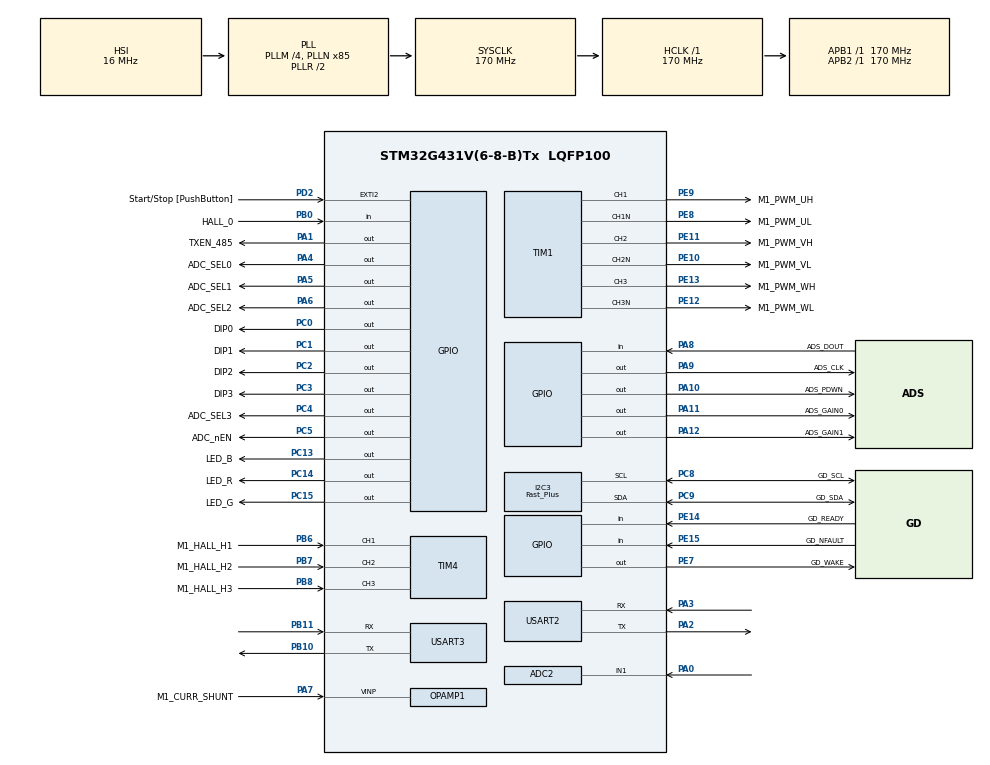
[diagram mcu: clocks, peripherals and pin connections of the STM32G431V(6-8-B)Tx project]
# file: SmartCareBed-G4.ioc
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ADC1.ClockPrescaler=ADC_CLOCK_ASYNC_DIV1
ADC1.ContinuousConvMode=DISABLE
ADC1.DMAContinuousRequests=DISABLE
ADC1.DataAlign=ADC_DATAALIGN_LEFT
ADC1.DiscontinuousConvMode=DISABLE
ADC1.EOCSelection=ADC_EOC_SINGLE_CONV
ADC1.EnableAnalogWatchDog1=false
ADC1.EnableAnalogWatchDog2=false
ADC1.EnableAnalogWatchDog3=false
ADC1.EnableInjectedConversion=ENABLE
ADC1.EnableRegularConversion=DISABLE
ADC1.ExternalTrigInjecConv=ADC_EXTERNALTRIGINJEC_T1_TRGO
ADC1.ExternalTrigInjecConvEdge=ADC_EXTERNALTRIGINJECCONV_EDGE_RISINGFALLING
ADC1.InjNumberOfConversion=2
ADC1.InjectedChannel-1\#ChannelInjectedConversion=ADC_CHANNEL_VOPAMP1
ADC1.InjectedChannel-2\#ChannelInjectedConversion=ADC_CHANNEL_VOPAMP1
ADC1.InjectedConvMode=None
ADC1.InjectedOffset-1\#ChannelInjectedConversion=0
ADC1.InjectedOffset-2\#ChannelInjectedConversion=0
ADC1.InjectedOffsetNumber-1\#ChannelInjectedConversion=ADC_OFFSET_NONE
ADC1.InjectedOffsetNumber-2\#ChannelInjectedConversion=ADC_OFFSET_NONE
ADC1.InjectedRank-1\#ChannelInjectedConversion=1
ADC1.InjectedRank-2\#ChannelInjectedConversion=2
ADC1.InjectedSamplingTime-1\#ChannelInjectedConversion=ADC_SAMPLETIME_6CYCLES_5
ADC1.InjectedSamplingTime-2\#ChannelInjectedConversion=ADC_SAMPLETIME_6CYCLES_5
ADC1.LowPowerAutoWait=DISABLE
ADC1.Overrun=ADC_OVR_DATA_PRESERVED
ADC1.Resolution=ADC_RESOLUTION_12B
ADC1.ScanConvMode=ADC_SCAN_ENABLE
ADC1.master=1
ADC2.Channel-1\#ChannelRegularConversion=ADC_CHANNEL_1
ADC2.ClockPrescaler=ADC_CLOCK_ASYNC_DIV1
ADC2.NbrOfConversionFlag=1
ADC2.OffsetNumber-1\#ChannelRegularConversion=ADC_OFFSET_NONE
ADC2.Rank-1\#ChannelRegularConversion=1
ADC2.SamplingTime-1\#ChannelRegularConversion=ADC_SAMPLETIME_2CYCLES_5
Dma.Request0=TIM1_CH4
Dma.TIM1_CH4.0.Direction=DMA_MEMORY_TO_PERIPH
Dma.TIM1_CH4.0.EventEnable=DISABLE
Dma.TIM1_CH4.0.Instance=DMA1_Channel1
Dma.TIM1_CH4.0.MemDataAlignment=DMA_MDATAALIGN_HALFWORD
Dma.TIM1_CH4.0.MemInc=DMA_MINC_ENABLE
Dma.TIM1_CH4.0.Mode=DMA_CIRCULAR
Dma.TIM1_CH4.0.PeriphDataAlignment=DMA_PDATAALIGN_HALFWORD
Dma.TIM1_CH4.0.PeriphInc=DMA_PINC_DISABLE
Dma.TIM1_CH4.0.Polarity=HAL_DMAMUX_REQ_GEN_RISING
Dma.TIM1_CH4.0.Priority=DMA_PRIORITY_HIGH
Dma.TIM1_CH4.0.RequestNumber=1
Dma.TIM1_CH4.0.SignalID=NONE
Dma.TIM1_CH4.0.SyncEnable=DISABLE
Dma.TIM1_CH4.0.SyncPolarity=HAL_DMAMUX_SYNC_NO_EVENT
Dma.TIM1_CH4.0.SyncRequestNumber=1
Dma.TIM1_CH4.0.SyncSignalID=NONE
ExtraMW=MotorControl
ExtraMW.MotorControl.Config=MotorControl
ExtraMW.MotorControl.Mode=MotorControl
ExtraMW.MotorControl.Root=MCSDK_v6.3.2-Full/MotorControl
ExtraMW.MotorControl.Template=templates
I2C3.I2C_Speed_Mode=I2C_Fast_Plus
I2C3.Timing=0x4052060F
Mcu.Family=STM32G4
Mcu.Name=STM32G431V(6-8-B)Tx
Mcu.Package=LQFP100
MotorControl.ADC_AHBPERIPH=RCC_AHBPeriph_ADC1
MotorControl.ADC_CLOCK_WB_DIV=1
MotorControl.ADC_PERIPH=ADC1
MotorControl.ADC_REFERENCE_VOLTAGE=3.3
MotorControl.BOARD=EVSPIN32G4
MotorControl.BUS_VOLTAGE_READING=false
MotorControl.CCMRAM_ENABLED=false
MotorControl.CLOCK_FREQUENCY=CPU_CLK_170_MHZ
MotorControl.CLOCK_SOURCE=INTERNAL
MotorControl.CPU_CLK_170_MHZ=true
MotorControl.CTLBOARD_NAME=EVSPIN32G4
MotorControl.CUBE_MX_VER=6.14.0
MotorControl.CURRENT_READING_TOPOLOGY=SINGLE_SHUNT
MotorControl.CURR_SAMPLING_TIME=6
MotorControl.DBG_MCU_LOAD_MEASURE=false
MotorControl.DEBUG_DAC_FUNCTIONALITY_EN=false
MotorControl.DRIVES_NUMBER_SELECTION=SINGLEDRIVE
MotorControl.DRIVE_NUMBER=1
MotorControl.DRIVE_TYPE=FOC
MotorControl.ENCODER_AVAILABLE=false
MotorControl.ENCODER_PPR=400
MotorControl.EXT_CLOCK_FREQUENCY=INT_RC_OSC
MotorControl.FEEDBACK_NET_FILTERING=false
MotorControl.FLASH_SIZE=128
MotorControl.H1_GPIO_PIN=LL_GPIO_PIN_6
MotorControl.H1_GPIO_PORT=GPIOB
MotorControl.H2_GPIO_PIN=LL_GPIO_PIN_7
MotorControl.H2_GPIO_PORT=GPIOB
MotorControl.H3_GPIO_PIN=LL_GPIO_PIN_8
MotorControl.H3_GPIO_PORT=GPIOB
MotorControl.HALL_ICx_FILTER=119
MotorControl.HALL_SENSORS=true
MotorControl.HALL_SENSORS_AVAILABLE=true
MotorControl.HALL_TIMER_SELECTION=HALL_TIM4
MotorControl.HIGH_SIDE_IDLE_STATE=false
MotorControl.HWV_CS=SingleShunt_RawCurrents_SingleEnded_InternalGain
MotorControl.HWV_PWM=PoweringHighAndLowSides
MotorControl.HW_COMPLEMENTED_LOW_SIDE=false
MotorControl.HW_DEAD_TIME_NS=1000
MotorControl.INT_RC_OSC=true
MotorControl.IPs=I2C3,CORDIC,SYS,NVIC,RCC,MotorControl,OPAMP1,ADC1,TIM1,TIM4,DMA
MotorControl.LOW_MEMORY_FOOTPRINT_REG=false
MotorControl.LOW_SIDE_IDLE_STATE=false
MotorControl.LOW_SIDE_SIGNALS_ENABLING=LS_PWM_TIMER
MotorControl.M1_AMPLIFICATION_GAIN=7.04
MotorControl.M1_ANGC={0,0,0,0,0,0,0,0}
MotorControl.M1_AUXILIARY_SPEED_SENSOR=NONE
MotorControl.M1_BOARD_MAX_CURRENT=1.5
MotorControl.M1_BUS_VOLTAGE_READING=false
MotorControl.M1_COMMUTATION_STEP_TIME_BUF_SIZE=12
MotorControl.M1_CONSTANT1_D=701888
MotorControl.M1_CONSTANT1_Q=701888
MotorControl.M1_CONSTANT2_QD=24322
MotorControl.M1_CS_ADC_NUM=1
MotorControl.M1_CS_ADC_PHASE_SHARED=NONE
MotorControl.M1_CS_ADC_U=ADC1
MotorControl.M1_CS_CHANNEL_U=VPOPAMP1
MotorControl.M1_CS_OPAMP_DIRECT_LINK_TO_ADC=ADC1
MotorControl.M1_CS_OPAMP_DYNAMIC_OUTPUT_SWITCH=false
MotorControl.M1_CS_OPAMP_NUM=1
MotorControl.M1_CS_OPAMP_PHASE_SHARED=NONE
MotorControl.M1_CS_OPAMP_U=OPAMP1
MotorControl.M1_CS_OPAMP_VPSEL_U=PA7
MotorControl.M1_CURRENT_AMPLIFICATION_TOPO=INT_SINGLE_ENDED
MotorControl.M1_CURRENT_SENSING_TOPO=SINGLE_SHUNT_PHASE_SHIFT
MotorControl.M1_CURR_SAMPLING_TIME=6
MotorControl.M1_DBG_OPEN_LOOP_ENABLE=false
MotorControl.M1_DC_CURRENT_RS_MEAS=1.5
MotorControl.M1_DEFAULT_CONTROL_MODE=STC_SPEED_MODE
MotorControl.M1_DEFAULT_FLUX_COMPONENT=0
MotorControl.M1_DEFAULT_TARGET_SPEED_RPM=4000
MotorControl.M1_DEFAULT_TORQUE_COMPONENT=0
MotorControl.M1_DISCONTINUOUS_PWM=false
MotorControl.M1_DP_TOPOLOGY=NONE
MotorControl.M1_DRIVE_TYPE=FOC
MotorControl.M1_ENCODER_PPR=400
MotorControl.M1_FEED_FORWARD_CURRENT_REG_ENABLING=false
MotorControl.M1_FLUX_WEAKENING_ENABLING=false
MotorControl.M1_FW_KIDIV=32768
MotorControl.M1_FW_KI_GAIN=5000
MotorControl.M1_FW_KPDIV=32768
MotorControl.M1_FW_KP_GAIN=3000
MotorControl.M1_FW_VOLTAGE_REF=985
MotorControl.M1_HALL_AVERAGING_FIFO_DEPTH=16
MotorControl.M1_HALL_ICx_FILTER=119
MotorControl.M1_HALL_MTPA=false
MotorControl.M1_HALL_PHASE_SHIFT=300
MotorControl.M1_HALL_SENSORS_PLACEMENT=DEGREES_120
MotorControl.M1_HALL_TIMER_IRQ=TIM4
MotorControl.M1_HALL_TIMER_SELECTION=HALL_TIM4
MotorControl.M1_HIGH_SIDE_IDLE_STATE=false
MotorControl.M1_HW_DEAD_TIME_NS=1000
MotorControl.M1_ICL_ENABLED=false
MotorControl.M1_ID_DEMAG=-1.5
MotorControl.M1_INT_AMP_OPAMP1_PIN=[{'mode'\:'Standalone','name'\:'PA7','signal'\:'OPAMP1_VINP','label'\:'SHUNT_P_P'}]
MotorControl.M1_INT_AMP_OPAMPS=['OPAMP1']
MotorControl.M1_IQMAX=1.5
MotorControl.M1_LDLQ_RATIO=1.000
MotorControl.M1_LOW_SIDE_IDLE_STATE=false
MotorControl.M1_LOW_SIDE_SIGNALS_ENABLING=LS_PWM_TIMER
MotorControl.M1_LS=0.0006
MotorControl.M1_MAX_APPLICATION_SPEED=4000
MotorControl.M1_MAX_MODULATION_INDEX=100
MotorControl.M1_MIN_APPLICATION_SPEED=0
MotorControl.M1_MOTOR_MAX_SPEED_RPM=4000
MotorControl.M1_MOTOR_NAME=Shinano LA052-080E3NL1
MotorControl.M1_MOTOR_RATED_FLUX=0.048989795
MotorControl.M1_MOTOR_VOLTAGE_CONSTANT=4.0
MotorControl.M1_MTPA_ENABLING=false
MotorControl.M1_NOMINAL_BUS_VOLTAGE_V=24
MotorControl.M1_NOMINAL_CURRENT=1.5
MotorControl.M1_OCP_TOPOLOGY=NONE
MotorControl.M1_OFST={0,0,0,0,0,0,0,0}
MotorControl.M1_OVERMODULATION=false
MotorControl.M1_PID_FLUX_KD_DEFAULT=100
MotorControl.M1_PID_FLUX_KI_DEFAULT=3360
MotorControl.M1_PID_FLUX_KP_DEFAULT=3600
MotorControl.M1_PID_SPEED_KD_DEFAULT=0
MotorControl.M1_PID_SPEED_KI_DEFAULT=362
MotorControl.M1_PID_SPEED_KP_DEFAULT=2019
MotorControl.M1_PID_TORQUE_KD_DEFAULT=100
MotorControl.M1_PID_TORQUE_KI_DEFAULT=3360
MotorControl.M1_PID_TORQUE_KP_DEFAULT=3600
MotorControl.M1_POLE_PAIR_NUM=4
MotorControl.M1_POSITION_CTRL_ENABLING=false
MotorControl.M1_POTENTIOMETER_ENABLE=false
MotorControl.M1_POWERBOARD_NAME=EVSPIN32G4
MotorControl.M1_PWM_CHARGE_BOOT_CAP_DUTY_CYCLES=0.000
MotorControl.M1_PWM_CHARGE_BOOT_CAP_MS=10
MotorControl.M1_PWM_DRIVER_PN=STSPIN32G4
MotorControl.M1_PWM_FREQUENCY=20000
MotorControl.M1_PWM_TIMER_BRK_IRQ=TIM1_BRK_TIM15
MotorControl.M1_PWM_TIMER_SELECTION=PWM_TIM1
MotorControl.M1_PWM_TIMER_UP_IRQ=TIM1_UP_TIM16
MotorControl.M1_REGULATION_EXECUTION_RATE=1
MotorControl.M1_RS=0.35
MotorControl.M1_RSHUNT=0.005
MotorControl.M1_SEGDIV=0
MotorControl.M1_SHARED_SIGNAL_ENABLE=false
MotorControl.M1_SPD_DIFFERENTIAL_TERM_ENABLING=false
MotorControl.M1_SPEED_LOOP_FREQUENCY_HZ=1000
MotorControl.M1_SPEED_SENSOR=HALL_SENSOR
MotorControl.M1_SP_KDDIV=16
MotorControl.M1_SP_KIDIV=16384
MotorControl.M1_SP_KPDIV=256
MotorControl.M1_SS_MEAS_ERRORS_BEFORE_FAULTS=3
MotorControl.M1_SW_DEADTIME_NS=750
MotorControl.M1_TEMPERATURE_READING=false
MotorControl.M1_TF_KDDIV=8192
MotorControl.M1_TF_KIDIV=8192
MotorControl.M1_TF_KPDIV=256
MotorControl.M1_TNOISE_NS=1200
MotorControl.M1_TRISE_NS=61
MotorControl.M1_USE_INTERNAL_OPAMP=true
MotorControl.MAX_READABLE_CURRENT=46.875
MotorControl.MCP_EN=false
MotorControl.MCU=STSPIN32G4
MotorControl.MCU_FAMILY=STM32G4
MotorControl.MCU_LINE=STM32G4x1
MotorControl.MCU_NAME=STM32G431V(6-8-B)Tx
MotorControl.MCU_PACKAGE=LQFP100
MotorControl.MCU_TYPE=STSPIN32G4
MotorControl.MCU_USERNAME=STM32G431VBTx
MotorControl.MC_WORKBENCH_VERSION=6.3.2
MotorControl.MOTOR_PROFILER=false
MotorControl.MOTOR_TYPE=PMSM
MotorControl.OPAMP_INVERTINGINPUT_MODE=INT_MODE
MotorControl.OPAMP_NONINVERTINGINPUT=OPAMP1_NonInvertingInput_PA7
MotorControl.OPAMP_NONINVERTINGINPUT_GPIO_PIN=LL_GPIO_PIN_7
MotorControl.OPAMP_NONINVERTINGINPUT_GPIO_PORT=GPIOA
MotorControl.OPAMP_PGAGAIN=OPAMP_OPAMP_PGAGain_8
MotorControl.OPAMP_SELECTION=OPAMP1
MotorControl.OPAMP_TYPE_GAIN=INTERNAL
MotorControl.PHASE_CURRENTS_ADC=ADC1
MotorControl.PHASE_CURRENTS_CHANNEL=ADC_Channel_VOPAMP1
MotorControl.PHASE_CURRENTS_GPIO_PIN=VIRTUAL_PIN
MotorControl.PHASE_CURRENTS_GPIO_PORT=VIRTUAL_PORT
MotorControl.PHASE_UH_GPIO_PIN=LL_GPIO_PIN_9
MotorControl.PHASE_UH_GPIO_PORT=GPIOE
MotorControl.PHASE_UH_POLARITY=H_ACTIVE_HIGH
MotorControl.PHASE_UL_GPIO_PIN=LL_GPIO_PIN_8
MotorControl.PHASE_UL_GPIO_PORT=GPIOE
MotorControl.PHASE_UL_POLARITY=L_ACTIVE_HIGH
MotorControl.PHASE_U_PWM_CHANNEL=TIM_Channel_1
MotorControl.PHASE_VH_GPIO_PIN=LL_GPIO_PIN_11
MotorControl.PHASE_VH_GPIO_PORT=GPIOE
MotorControl.PHASE_VH_POLARITY=H_ACTIVE_HIGH
MotorControl.PHASE_VL_GPIO_PIN=LL_GPIO_PIN_10
MotorControl.PHASE_VL_GPIO_PORT=GPIOE
MotorControl.PHASE_VL_POLARITY=L_ACTIVE_HIGH
MotorControl.PHASE_V_PWM_CHANNEL=TIM_Channel_2
MotorControl.PHASE_WH_GPIO_PIN=LL_GPIO_PIN_13
MotorControl.PHASE_WH_GPIO_PORT=GPIOE
MotorControl.PHASE_WH_POLARITY=H_ACTIVE_HIGH
MotorControl.PHASE_WL_GPIO_PIN=LL_GPIO_PIN_12
MotorControl.PHASE_WL_GPIO_PORT=GPIOE
MotorControl.PHASE_WL_POLARITY=L_ACTIVE_HIGH
MotorControl.PHASE_W_PWM_CHANNEL=TIM_Channel_3
MotorControl.POTENTIOMETER_READING=false
MotorControl.PWM_FREQUENCY=20000
MotorControl.PWM_TIMER_SELECTION=PWM_TIM1
MotorControl.REGULATION_EXECUTION_RATE=1
MotorControl.RTOS=NONE
MotorControl.SINGLEDRIVE=true
MotorControl.SINGLE_SHUNT=true
MotorControl.SPD_DIFFERENTIAL_TERM_ENABLING=false
MotorControl.SPEED_SENSOR_SELECTION=HALL_SENSORS
MotorControl.START_STOP_BTN=true
MotorControl.START_STOP_GPIO_PIN=LL_GPIO_PIN_10
MotorControl.START_STOP_GPIO_PORT=GPIOB
MotorControl.START_STOP_POLARITY=DIN_ACTIVE_HIGH
MotorControl.START_STOP_POLARITY_EDGE=GPIO_NOPULL
MotorControl.STSPIN32G4=true
MotorControl.SW_DEADTIME_NS=750
MotorControl.TEMPERATURE_READING=false
MotorControl.TFDIFFERENTIAL_TERM_ENABLING=false
MotorControl.TRISE_NS=61
MotorControl.USE_3OPAMPS=false
MotorControl.USE_INTERNAL_OPAMP=true
MotorControl.WB_UI_CUTOFF_FREQUENCY=6000
MotorControl.WB_UI_ENCODER_HAS_INDEX_PIN=false
MotorControl.WB_UI_FLUX_TARGET=0
MotorControl.WB_UI_FRICTION=14
MotorControl.WB_UI_GAIN=7.04
MotorControl.WB_UI_GAINLIST=[{'factor'\:2,'gain'\:1.76,'pol'\:0.396,'maxVRef'\:3.3},{'factor'\:4,'gain'\:3.52,'pol'\:0.792,'maxVRef'\:3.3},{'factor'\:8,'gain'\:7.04,'pol'\:1.584,'maxVRef'\:3.3},{'factor'\:16,'gain'\:14.08,'pol'\:3.168,'maxVRef'\:3.3},{'factor'\:32,'gain'\:28.16,'pol'\:6.336,'maxVRef'\:3.3},{'factor'\:64,'gain'\:56.32,'pol'\:12.672,'maxVRef'\:3.3}]
MotorControl.WB_UI_GON=0.88
MotorControl.WB_UI_GOP=8
MotorControl.WB_UI_INERTIA=5
MotorControl.WB_UI_MAGNETIC_STRUCTURE=SM-PMSM
MotorControl.WB_UI_MAX_CURRENT=1.5
MotorControl.WB_UI_MAX_NOMINAL_DC_VOLTAGE=24
MotorControl.WB_UI_MAX_PWMFREQUENCY=100000
MotorControl.WB_UI_MOTOR_DESCRIPTION=Inner rotor type - 2 poles pairs - brushless DC motor with encoder
MotorControl.WB_UI_PW_BOARD_MAX_RATED_CURRENT=20
MotorControl.WB_UI_PW_BOARD_MAX_VOLTAGE=75
MotorControl.WB_UI_PW_BOARD_MIN_VOLTAGE=10
MotorControl.WB_UI_VPOL=1.5840633625
MotorControl.WB_UI_VPOL_K=0.1980079203
MotorControl.WB_to_Mx_template_version=24-04-17
MotorControl.WB_to_Mx_version=6.2.3
NVIC.ADC1_2_IRQn=true\:2\:0\:true\:true\:false\:2\:true\:true\:true
NVIC.DMA1_Channel1_IRQn=true\:0\:0\:true\:true\:false\:1\:true\:true\:true
NVIC.EXTI2_IRQn=true\:3\:0\:true\:false\:true\:true\:true\:true
NVIC.PriorityGroup=NVIC_PRIORITYGROUP_3
NVIC.TIM1_BRK_TIM15_IRQn=true\:4\:1\:true\:true\:false\:3\:true\:true\:true
NVIC.TIM1_UP_TIM16_IRQn=true\:0\:0\:false\:true\:false\:4\:true\:true\:true
NVIC.TIM4_IRQn=true\:3\:0\:false\:true\:false\:5\:true\:true\:true
OPAMP1.PgaGain=OPAMP_PGA_GAIN_8_OR_MINUS_7
OPAMP1.SelfCalibration=Disable
PA0.Mode=IN1-Single-Ended
PA0.Signal=ADC2_IN1
PA1.GPIO_Label=TXEN_485
PA1.Signal=GPIO_Output
PA10.GPIO_Label=ADS_PDWN
PA10.Signal=GPIO_Output
PA11.GPIO_Label=ADS_GAIN0
PA11.Signal=GPIO_Output
PA12.GPIO_Label=ADS_GAIN1
PA12.Signal=GPIO_Output
PA13.GPIO_Label=TMS
PA13.Mode=Serial_Wire
PA13.Signal=SYS_JTMS-SWDIO
PA14.GPIO_Label=TCK
PA14.Mode=Serial_Wire
PA14.Signal=SYS_JTCK-SWCLK
PA2.Mode=Asynchronous
PA2.Signal=USART2_TX
PA3.Mode=Asynchronous
PA3.Signal=USART2_RX
PA4.GPIO_Label=ADC_SEL0
PA4.Signal=GPIO_Output
PA5.GPIO_Label=ADC_SEL1
PA5.Signal=GPIO_Output
PA6.GPIO_Label=ADC_SEL2
PA6.Signal=GPIO_Output
PA7.GPIO_Label=M1_CURR_SHUNT
PA7.Mode=PGA_Internally_Connected
PA7.Signal=OPAMP1_VINP
PA8.GPIO_Label=ADS_DOUT
PA8.Signal=GPIO_Input
PA9.GPIO_Label=ADS_CLK
PA9.Signal=GPIO_Output
PB0.GPIO_Label=HALL_0
PB0.Signal=GPIO_Input
PB10.Mode=Asynchronous
PB10.Signal=USART3_TX
PB11.Mode=Asynchronous
PB11.Signal=USART3_RX
PB6.GPIO_Label=M1_HALL_H1
PB6.GPIO_Speed=GPIO_SPEED_FREQ_HIGH
PB6.Signal=S_TIM4_CH1
PB7.GPIO_Label=M1_HALL_H2
PB7.GPIO_Speed=GPIO_SPEED_FREQ_HIGH
PB7.Signal=S_TIM4_CH2
PB8-BOOT0.GPIO_Label=M1_HALL_H3
PB8-BOOT0.GPIO_Speed=GPIO_SPEED_FREQ_HIGH
PB8-BOOT0.Signal=S_TIM4_CH3
PC0.GPIO_Label=DIP0
PC0.Signal=GPIO_Output
PC1.GPIO_Label=DIP1
PC1.Signal=GPIO_Output
PC13.GPIO_Label=LED_B
PC13.Signal=GPIO_Output
PC14-OSC32_IN.GPIO_Label=LED_R
PC14-OSC32_IN.Signal=GPIO_Output
PC15-OSC32_OUT.GPIO_Label=LED_G
PC15-OSC32_OUT.Signal=GPIO_Output
PC2.GPIO_Label=DIP2
PC2.Signal=GPIO_Output
PC3.GPIO_Label=DIP3
PC3.Signal=GPIO_Output
PC4.GPIO_Label=ADC_SEL3
PC4.Signal=GPIO_Output
PC5.GPIO_Label=ADC_nEN
PC5.Signal=GPIO_Output
PC8.GPIO_Label=GD_SCL
PC8.Mode=I2C
PC8.Signal=I2C3_SCL
PC9.GPIO_Label=GD_SDA
PC9.Mode=I2C
PC9.Signal=I2C3_SDA
PD2.GPIO_Label=Start/Stop [PushButton]
PD2.Signal=GPXTI2
PE10.GPIO_Label=M1_PWM_VL
PE10.GPIO_PuPd=GPIO_PULLDOWN
PE10.GPIO_Speed=GPIO_SPEED_FREQ_HIGH
PE10.Mode=PWM Generation2 CH2 CH2N
PE10.Signal=TIM1_CH2N
PE11.GPIO_Label=M1_PWM_VH
PE11.GPIO_PuPd=GPIO_PULLDOWN
PE11.GPIO_Speed=GPIO_SPEED_FREQ_HIGH
PE11.Signal=S_TIM1_CH2
PE12.GPIO_Label=M1_PWM_WL
PE12.GPIO_PuPd=GPIO_PULLDOWN
PE12.GPIO_Speed=GPIO_SPEED_FREQ_HIGH
PE12.Mode=PWM Generation3 CH3 CH3N
PE12.Signal=TIM1_CH3N
PE13.GPIO_Label=M1_PWM_WH
PE13.GPIO_PuPd=GPIO_PULLDOWN
PE13.GPIO_Speed=GPIO_SPEED_FREQ_HIGH
PE13.Signal=S_TIM1_CH3
PE14.GPIO_Label=GD_READY
PE14.GPIO_PuPd=GPIO_PULLUP
PE14.Signal=GPIO_Input
PE15.GPIO_Label=GD_NFAULT
PE15.GPIO_PuPd=GPIO_PULLUP
PE15.Signal=GPIO_Input
PE7.GPIO_Label=GD_WAKE
PE7.PinState=GPIO_PIN_SET
PE7.Signal=GPIO_Output
PE8.GPIO_Label=M1_PWM_UL
PE8.GPIO_PuPd=GPIO_PULLDOWN
PE8.GPIO_Speed=GPIO_SPEED_FREQ_HIGH
PE8.Mode=PWM Generation1 CH1 CH1N
PE8.Signal=TIM1_CH1N
PE9.GPIO_Label=M1_PWM_UH
PE9.GPIO_PuPd=GPIO_PULLDOWN
PE9.GPIO_Speed=GPIO_SPEED_FREQ_HIGH
PE9.Signal=S_TIM1_CH1
ProjectManager.HeapSize=0x200
ProjectManager.StackSize=0x400
ProjectManager.TargetToolchain=STM32CubeIDE
RCC.ADC12CLockSelection=RCC_ADC12CLKSOURCE_PLL
RCC.ADC12Freq_Value=42500000
RCC.AHBFreq_Value=170000000
RCC.APB1Freq_Value=170000000
RCC.APB1TimFreq_Value=170000000
RCC.APB2Freq_Value=170000000
RCC.APB2TimFreq_Value=170000000
RCC.CK48CLockSelection=RCC_USBCLKSOURCE_PLL
RCC.CortexFreq_Value=170000000
RCC.EXTERNAL_CLOCK_VALUE=12288000
RCC.HCLKFreq_Value=170000000
RCC.HSE_VALUE=8000000
RCC.HSI48_VALUE=48000000
RCC.HSI_VALUE=16000000
RCC.LSE_VALUE=32768
RCC.PLLM=RCC_PLLM_DIV4
RCC.PLLN=85
RCC.PLLP=RCC_PLLP_DIV8
RCC.PREFETCH_ENABLE=1
RCC.SYSCLKFreq_VALUE=170000000
RCC.SYSCLKSource=RCC_SYSCLKSOURCE_PLLCLK
RCC.USBFreq_Value=170000000
RCC.VCOOutputFreq_Value=340000000
SH.S_TIM1_CH1.0=TIM1_CH1,PWM Generation1 CH1 CH1N
SH.S_TIM1_CH2.0=TIM1_CH2,PWM Generation2 CH2 CH2N
SH.S_TIM1_CH3.0=TIM1_CH3,PWM Generation3 CH3 CH3N
SH.S_TIM4_CH1.0=TIM4_CH1,Xored_Inputs_Hall_Sensor_Interface
SH.S_TIM4_CH2.0=TIM4_CH2,Xored_Inputs_Hall_Sensor_Interface
SH.S_TIM4_CH3.0=TIM4_CH3,Xored_Inputs_Hall_Sensor_Interface
TIM1.AutoReloadPreload=TIM_AUTORELOAD_PRELOAD_DISABLE
TIM1.AutomaticOutput=TIM_AUTOMATICOUTPUT_DISABLE
TIM1.Break2Filter=3
TIM1.Break2Polarity=TIM_BREAK2POLARITY_HIGH
TIM1.Break2State=TIM_BREAK2_DISABLE
TIM1.BreakFilter=0
TIM1.BreakPolarity=TIM_BREAKPOLARITY_HIGH
TIM1.BreakState=TIM_BREAK_DISABLE
TIM1.Channel=TIM_CHANNEL_6
TIM1.Channel-PWM\ Generation1\ CH1\ CH1N=TIM_CHANNEL_1
TIM1.Channel-PWM\ Generation2\ CH2\ CH2N=TIM_CHANNEL_2
TIM1.Channel-PWM\ Generation3\ CH3\ CH3N=TIM_CHANNEL_3
TIM1.Channel-PWM\ Generation4\ No\ Output=TIM_CHANNEL_4
TIM1.Channel-PWM\ Generation5\ No\ Output=TIM_CHANNEL_5
TIM1.Channel-PWM\ Generation6\ No\ Output=TIM_CHANNEL_6
TIM1.ClearInputSource=TIM_CLEARINPUTSOURCE_NONE
TIM1.ClockDivision=TIM_CLOCKDIVISION_DIV2
TIM1.CounterMode=TIM_COUNTERMODE_CENTERALIGNED2
TIM1.DeadTime=((DEAD_TIME_COUNTS) / 2)
TIM1.LockLevel=TIM_LOCKLEVEL_OFF
TIM1.OC1Preload_PWM=ENABLE
TIM1.OC2Preload_PWM=ENABLE
TIM1.OC3Preload_PWM=ENABLE
TIM1.OC4Preload_PWM=ENABLE
TIM1.OC5Preload_PWM=ENABLE
TIM1.OC6Preload_PWM=ENABLE
TIM1.OCFastMode_PWM=TIM_OCFAST_DISABLE
TIM1.OCIdleState_1=TIM_OCIDLESTATE_RESET
TIM1.OCIdleState_2=TIM_OCIDLESTATE_RESET
TIM1.OCIdleState_3=TIM_OCIDLESTATE_RESET
TIM1.OCIdleState_4=TIM_OCIDLESTATE_RESET
TIM1.OCIdleState_5=TIM_OCIDLESTATE_RESET
TIM1.OCIdleState_6=TIM_OCIDLESTATE_RESET
TIM1.OCMode_PWM-PWM\ Generation1\ CH1\ CH1N=TIM_OCMODE_PWM1
TIM1.OCMode_PWM-PWM\ Generation2\ CH2\ CH2N=TIM_OCMODE_PWM1
TIM1.OCMode_PWM-PWM\ Generation3\ CH3\ CH3N=TIM_OCMODE_PWM1
TIM1.OCMode_PWM-PWM\ Generation4\ No\ Output=TIM_OCMODE_PWM2
TIM1.OCMode_PWM-PWM\ Generation5\ No\ Output=TIM_OCMODE_PWM2
TIM1.OCMode_PWM-PWM\ Generation6\ No\ Output=TIM_OCMODE_PWM2
TIM1.OCNIdleState_1=TIM_OCNIDLESTATE_RESET
TIM1.OCNIdleState_2=TIM_OCNIDLESTATE_RESET
TIM1.OCNIdleState_3=TIM_OCNIDLESTATE_RESET
TIM1.OCNPolarity_1=TIM_OCNPOLARITY_HIGH
TIM1.OCNPolarity_2=TIM_OCNPOLARITY_HIGH
TIM1.OCNPolarity_3=TIM_OCNPOLARITY_HIGH
TIM1.OCPolarity_1=TIM_OCPOLARITY_HIGH
TIM1.OCPolarity_2=TIM_OCPOLARITY_HIGH
TIM1.OCPolarity_3=TIM_OCPOLARITY_HIGH
TIM1.OCPolarity_4=TIM_OCPOLARITY_HIGH
TIM1.OCPolarity_5=TIM_OCPOLARITY_HIGH
TIM1.OCPolarity_6=TIM_OCPOLARITY_HIGH
TIM1.OffStateIDLEMode=TIM_OSSI_ENABLE
TIM1.OffStateRunMode=TIM_OSSR_ENABLE
TIM1.PeriodNoDither=((PWM_PERIOD_CYCLES) / 2)
TIM1.Prescaler=((TIM_CLOCK_DIVIDER) - 1)
TIM1.PulseNoDither_1=((PWM_PERIOD_CYCLES) / 4)
TIM1.PulseNoDither_2=((PWM_PERIOD_CYCLES) / 4)
TIM1.PulseNoDither_3=((PWM_PERIOD_CYCLES) / 4)
TIM1.PulseNoDither_4=(((PWM_PERIOD_CYCLES) / 2) - (HTMIN))
TIM1.PulseNoDither_5=(((PWM_PERIOD_CYCLES) / 2) + 1)
TIM1.PulseNoDither_6=(((PWM_PERIOD_CYCLES) / 2) + 1)
TIM1.RepetitionCounter=(REP_COUNTER)
TIM1.SourceBRK2DigInput=TIM_BREAKINPUTSOURCE_DISABLE
TIM1.SourceBRKDigInput=TIM_BREAKINPUTSOURCE_DISABLE
TIM1.TIM_MasterOutputTrigger=TIM_TRGO_RESET
TIM1.TIM_MasterOutputTrigger2=TIM_TRGO2_OC5REF_RISING_OC6REF_RISING
TIM1.TIM_MasterSlaveMode=TIM_MASTERSLAVEMODE_DISABLE
TIM1.TIM_SlaveMode=TIM_SLAVEMODE_TRIGGER
TIM4.IC1Filter=M1_HALL_IC_FILTER
TIM4.PeriodNoDither=M1_HALL_TIM_PERIOD
USART2.VirtualMode-Asynchronous=VM_ASYNC
USART3.VirtualMode-Asynchronous=VM_ASYNC
VP_ADC1_OPAMP_INTERNAL1.Mode=IN-OPAMP1
VP_CORDIC_VS_CORDIC.Mode=CORDIC_Activate
VP_MotorControl_MC_ENABLED.Mode=Enabled
VP_SYS_VS_DBSignals.Mode=DisableDeadBatterySignals
VP_TIM1_VS_no_output4.Mode=PWM Generation4 No Output
VP_TIM1_VS_no_output5.Mode=PWM Generation5 No Output
VP_TIM1_VS_no_output6.Mode=PWM Generation6 No Output
VP_TIM4_VS_ClockSourceINT.Mode=Internal
board=custom

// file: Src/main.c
/* USER CODE BEGIN Header */
/**
  ******************************************************************************
  * @file           : main.c
  * @brief          : Main program body
  ******************************************************************************
  * @attention
  *
  * Copyright (c) 2025 STMicroelectronics.
  * All rights reserved.
  *
  * This software is licensed under terms that can be found in the LICENSE file
  * in the root directory of this software component.
  * If no LICENSE file comes with this software, it is provided AS-IS.
  *
  ******************************************************************************
  */
/* USER CODE END Header */
#include "main.h"

ADC_HandleTypeDef hadc1;
ADC_HandleTypeDef hadc2;

CORDIC_HandleTypeDef hcordic;

I2C_HandleTypeDef hi2c3;

OPAMP_HandleTypeDef hopamp1;

TIM_HandleTypeDef htim1;
TIM_HandleTypeDef htim4;
DMA_HandleTypeDef hdma_tim1_ch4;

UART_HandleTypeDef huart2;
UART_HandleTypeDef huart3;

void SystemClock_Config(void);
static void MX_GPIO_Init(void);
static void MX_DMA_Init(void);
static void MX_ADC1_Init(void);
static void MX_CORDIC_Init(void);
static void MX_I2C3_Init(void);
static void MX_OPAMP1_Init(void);
static void MX_TIM1_Init(void);
static void MX_TIM4_Init(void);
static void MX_ADC2_Init(void);
static void MX_USART2_UART_Init(void);
static void MX_USART3_UART_Init(void);
static void MX_NVIC_Init(void);

int main(void)
{

  /* MCU Configuration--------------------------------------------------------*/

  /* Reset of all peripherals, Initializes the Flash interface and the Systick. */
  HAL_Init();

  /* Configure the system clock */
  SystemClock_Config();

  /* Initialize all configured peripherals */
  MX_GPIO_Init();
  MX_DMA_Init();
  MX_ADC1_Init();
  MX_CORDIC_Init();
  MX_I2C3_Init();
  MX_OPAMP1_Init();
  MX_TIM1_Init();
  MX_TIM4_Init();
  MX_MotorControl_Init();
  MX_ADC2_Init();
  MX_USART2_UART_Init();
  MX_USART3_UART_Init();

  /* Initialize interrupts */
  MX_NVIC_Init();

  /* Infinite loop */
  /* USER CODE BEGIN WHILE */
  while (1)
  {
	  MC_StartMotor1();
    /* USER CODE END WHILE */

  }
}

void SystemClock_Config(void)
{
  RCC_OscInitTypeDef RCC_OscInitStruct = {0};
  RCC_ClkInitTypeDef RCC_ClkInitStruct = {0};

  /** Configure the main internal regulator output voltage
  */
  HAL_PWREx_ControlVoltageScaling(PWR_REGULATOR_VOLTAGE_SCALE1_BOOST);

  /** Initializes the RCC Oscillators according to the specified parameters
  * in the RCC_OscInitTypeDef structure.
  */
  RCC_OscInitStruct.OscillatorType = RCC_OSCILLATORTYPE_HSI;
  RCC_OscInitStruct.HSIState = RCC_HSI_ON;
  RCC_OscInitStruct.HSICalibrationValue = RCC_HSICALIBRATION_DEFAULT;
  RCC_OscInitStruct.PLL.PLLState = RCC_PLL_ON;
  RCC_OscInitStruct.PLL.PLLSource = RCC_PLLSOURCE_HSI;
  RCC_OscInitStruct.PLL.PLLM = RCC_PLLM_DIV4;
  RCC_OscInitStruct.PLL.PLLN = 85;
  RCC_OscInitStruct.PLL.PLLP = RCC_PLLP_DIV8;
  RCC_OscInitStruct.PLL.PLLQ = RCC_PLLQ_DIV2;
  RCC_OscInitStruct.PLL.PLLR = RCC_PLLR_DIV2;
  if (HAL_RCC_OscConfig(&RCC_OscInitStruct) != HAL_OK)
  {
    Error_Handler();
  }

  /** Initializes the CPU, AHB and APB buses clocks
  */
  RCC_ClkInitStruct.ClockType = RCC_CLOCKTYPE_HCLK|RCC_CLOCKTYPE_SYSCLK
                              |RCC_CLOCKTYPE_PCLK1|RCC_CLOCKTYPE_PCLK2;
  RCC_ClkInitStruct.SYSCLKSource = RCC_SYSCLKSOURCE_PLLCLK;
  RCC_ClkInitStruct.AHBCLKDivider = RCC_SYSCLK_DIV1;
  RCC_ClkInitStruct.APB1CLKDivider = RCC_HCLK_DIV1;
  RCC_ClkInitStruct.APB2CLKDivider = RCC_HCLK_DIV1;

  if (HAL_RCC_ClockConfig(&RCC_ClkInitStruct, FLASH_LATENCY_4) != HAL_OK)
  {
    Error_Handler();
  }
}

/**
  * @brief NVIC Configuration.
  * @retval None
  */
static void MX_NVIC_Init(void)
{
  /* DMA1_Channel1_IRQn interrupt configuration */
  HAL_NVIC_SetPriority(DMA1_Channel1_IRQn, 0, 0);
  HAL_NVIC_EnableIRQ(DMA1_Channel1_IRQn);
  /* ADC1_2_IRQn interrupt configuration */
  HAL_NVIC_SetPriority(ADC1_2_IRQn, 2, 0);
  HAL_NVIC_EnableIRQ(ADC1_2_IRQn);
  /* TIM1_BRK_TIM15_IRQn interrupt configuration */
  HAL_NVIC_SetPriority(TIM1_BRK_TIM15_IRQn, 4, 1);
  HAL_NVIC_EnableIRQ(TIM1_BRK_TIM15_IRQn);
  /* TIM1_UP_TIM16_IRQn interrupt configuration */
  HAL_NVIC_SetPriority(TIM1_UP_TIM16_IRQn, 0, 0);
  HAL_NVIC_EnableIRQ(TIM1_UP_TIM16_IRQn);
  /* TIM4_IRQn interrupt configuration */
  HAL_NVIC_SetPriority(TIM4_IRQn, 3, 0);
  HAL_NVIC_EnableIRQ(TIM4_IRQn);
}

static void MX_ADC1_Init(void)
{

  ADC_MultiModeTypeDef multimode = {0};
  ADC_InjectionConfTypeDef sConfigInjected = {0};

  /** Common config
  */
  hadc1.Instance = ADC1;
  hadc1.Init.ClockPrescaler = ADC_CLOCK_ASYNC_DIV1;
  hadc1.Init.Resolution = ADC_RESOLUTION_12B;
  hadc1.Init.DataAlign = ADC_DATAALIGN_LEFT;
  hadc1.Init.GainCompensation = 0;
  hadc1.Init.ScanConvMode = ADC_SCAN_ENABLE;
  hadc1.Init.EOCSelection = ADC_EOC_SINGLE_CONV;
  hadc1.Init.LowPowerAutoWait = DISABLE;
  hadc1.Init.ContinuousConvMode = DISABLE;
  hadc1.Init.NbrOfConversion = 1;
  hadc1.Init.DiscontinuousConvMode = DISABLE;
  hadc1.Init.DMAContinuousRequests = DISABLE;
  hadc1.Init.Overrun = ADC_OVR_DATA_PRESERVED;
  hadc1.Init.OversamplingMode = DISABLE;
  if (HAL_ADC_Init(&hadc1) != HAL_OK)
  {
    Error_Handler();
  }

  /** Configure the ADC multi-mode
  */
  multimode.Mode = ADC_MODE_INDEPENDENT;
  if (HAL_ADCEx_MultiModeConfigChannel(&hadc1, &multimode) != HAL_OK)
  {
    Error_Handler();
  }

  /** Configure Injected Channel
  */
  sConfigInjected.InjectedChannel = ADC_CHANNEL_VOPAMP1;
  sConfigInjected.InjectedRank = ADC_INJECTED_RANK_1;
  sConfigInjected.InjectedSamplingTime = ADC_SAMPLETIME_6CYCLES_5;
  sConfigInjected.InjectedSingleDiff = ADC_SINGLE_ENDED;
  sConfigInjected.InjectedOffsetNumber = ADC_OFFSET_NONE;
  sConfigInjected.InjectedOffset = 0;
  sConfigInjected.InjectedNbrOfConversion = 2;
  sConfigInjected.InjectedDiscontinuousConvMode = DISABLE;
  sConfigInjected.AutoInjectedConv = DISABLE;
  sConfigInjected.QueueInjectedContext = DISABLE;
  sConfigInjected.ExternalTrigInjecConv = ADC_EXTERNALTRIGINJEC_T1_TRGO;
  sConfigInjected.ExternalTrigInjecConvEdge = ADC_EXTERNALTRIGINJECCONV_EDGE_RISINGFALLING;
  sConfigInjected.InjecOversamplingMode = DISABLE;
  if (HAL_ADCEx_InjectedConfigChannel(&hadc1, &sConfigInjected) != HAL_OK)
  {
    Error_Handler();
  }

  /** Configure Injected Channel
  */
  sConfigInjected.InjectedRank = ADC_INJECTED_RANK_2;
  if (HAL_ADCEx_InjectedConfigChannel(&hadc1, &sConfigInjected) != HAL_OK)
  {
    Error_Handler();
  }

}

static void MX_ADC2_Init(void)
{

  ADC_ChannelConfTypeDef sConfig = {0};

  /** Common config
  */
  hadc2.Instance = ADC2;
  hadc2.Init.ClockPrescaler = ADC_CLOCK_ASYNC_DIV1;
  hadc2.Init.Resolution = ADC_RESOLUTION_12B;
  hadc2.Init.DataAlign = ADC_DATAALIGN_RIGHT;
  hadc2.Init.GainCompensation = 0;
  hadc2.Init.ScanConvMode = ADC_SCAN_DISABLE;
  hadc2.Init.EOCSelection = ADC_EOC_SINGLE_CONV;
  hadc2.Init.LowPowerAutoWait = DISABLE;
  hadc2.Init.ContinuousConvMode = DISABLE;
  hadc2.Init.NbrOfConversion = 1;
  hadc2.Init.DiscontinuousConvMode = DISABLE;
  hadc2.Init.ExternalTrigConv = ADC_SOFTWARE_START;
  hadc2.Init.ExternalTrigConvEdge = ADC_EXTERNALTRIGCONVEDGE_NONE;
  hadc2.Init.DMAContinuousRequests = DISABLE;
  hadc2.Init.Overrun = ADC_OVR_DATA_PRESERVED;
  hadc2.Init.OversamplingMode = DISABLE;
  if (HAL_ADC_Init(&hadc2) != HAL_OK)
  {
    Error_Handler();
  }

  /** Configure Regular Channel
  */
  sConfig.Channel = ADC_CHANNEL_1;
  sConfig.Rank = ADC_REGULAR_RANK_1;
  sConfig.SamplingTime = ADC_SAMPLETIME_2CYCLES_5;
  sConfig.SingleDiff = ADC_SINGLE_ENDED;
  sConfig.OffsetNumber = ADC_OFFSET_NONE;
  sConfig.Offset = 0;
  if (HAL_ADC_ConfigChannel(&hadc2, &sConfig) != HAL_OK)
  {
    Error_Handler();
  }

}

static void MX_CORDIC_Init(void)
{

  hcordic.Instance = CORDIC;
  if (HAL_CORDIC_Init(&hcordic) != HAL_OK)
  {
    Error_Handler();
  }

}

static void MX_I2C3_Init(void)
{

  hi2c3.Instance = I2C3;
  hi2c3.Init.Timing = 0x4052060F;
  hi2c3.Init.OwnAddress1 = 0;
  hi2c3.Init.AddressingMode = I2C_ADDRESSINGMODE_7BIT;
  hi2c3.Init.DualAddressMode = I2C_DUALADDRESS_DISABLE;
  hi2c3.Init.OwnAddress2 = 0;
  hi2c3.Init.OwnAddress2Masks = I2C_OA2_NOMASK;
  hi2c3.Init.GeneralCallMode = I2C_GENERALCALL_DISABLE;
  hi2c3.Init.NoStretchMode = I2C_NOSTRETCH_DISABLE;
  if (HAL_I2C_Init(&hi2c3) != HAL_OK)
  {
    Error_Handler();
  }

  /** Configure Analogue filter
  */
  if (HAL_I2CEx_ConfigAnalogFilter(&hi2c3, I2C_ANALOGFILTER_ENABLE) != HAL_OK)
  {
    Error_Handler();
  }

  /** Configure Digital filter
  */
  if (HAL_I2CEx_ConfigDigitalFilter(&hi2c3, 0) != HAL_OK)
  {
    Error_Handler();
  }

  /** I2C Fast mode Plus enable
  */
  HAL_I2CEx_EnableFastModePlus(I2C_FASTMODEPLUS_I2C3);

}

static void MX_OPAMP1_Init(void)
{

  hopamp1.Instance = OPAMP1;
  hopamp1.Init.PowerMode = OPAMP_POWERMODE_NORMALSPEED;
  hopamp1.Init.Mode = OPAMP_PGA_MODE;
  hopamp1.Init.NonInvertingInput = OPAMP_NONINVERTINGINPUT_IO2;
  hopamp1.Init.InternalOutput = ENABLE;
  hopamp1.Init.TimerControlledMuxmode = OPAMP_TIMERCONTROLLEDMUXMODE_DISABLE;
  hopamp1.Init.PgaConnect = OPAMP_PGA_CONNECT_INVERTINGINPUT_NO;
  hopamp1.Init.PgaGain = OPAMP_PGA_GAIN_8_OR_MINUS_7;
  hopamp1.Init.UserTrimming = OPAMP_TRIMMING_FACTORY;
  if (HAL_OPAMP_Init(&hopamp1) != HAL_OK)
  {
    Error_Handler();
  }

}

static void MX_TIM1_Init(void)
{

  TIM_MasterConfigTypeDef sMasterConfig = {0};
  TIM_OC_InitTypeDef sConfigOC = {0};
  TIM_BreakDeadTimeConfigTypeDef sBreakDeadTimeConfig = {0};

  htim1.Instance = TIM1;
  htim1.Init.Prescaler = ((TIM_CLOCK_DIVIDER) - 1);
  htim1.Init.CounterMode = TIM_COUNTERMODE_CENTERALIGNED2;
  htim1.Init.Period = ((PWM_PERIOD_CYCLES) / 2);
  htim1.Init.ClockDivision = TIM_CLOCKDIVISION_DIV2;
  htim1.Init.RepetitionCounter = (REP_COUNTER);
  htim1.Init.AutoReloadPreload = TIM_AUTORELOAD_PRELOAD_DISABLE;
  if (HAL_TIM_PWM_Init(&htim1) != HAL_OK)
  {
    Error_Handler();
  }
  sMasterConfig.MasterOutputTrigger = TIM_TRGO_RESET;
  sMasterConfig.MasterOutputTrigger2 = TIM_TRGO2_OC5REF_RISING_OC6REF_RISING;
  sMasterConfig.MasterSlaveMode = TIM_MASTERSLAVEMODE_DISABLE;
  if (HAL_TIMEx_MasterConfigSynchronization(&htim1, &sMasterConfig) != HAL_OK)
  {
    Error_Handler();
  }
  sConfigOC.OCMode = TIM_OCMODE_PWM1;
  sConfigOC.Pulse = ((PWM_PERIOD_CYCLES) / 4);
  sConfigOC.OCPolarity = TIM_OCPOLARITY_HIGH;
  sConfigOC.OCNPolarity = TIM_OCNPOLARITY_HIGH;
  sConfigOC.OCFastMode = TIM_OCFAST_DISABLE;
  sConfigOC.OCIdleState = TIM_OCIDLESTATE_RESET;
  sConfigOC.OCNIdleState = TIM_OCNIDLESTATE_RESET;
  if (HAL_TIM_PWM_ConfigChannel(&htim1, &sConfigOC, TIM_CHANNEL_1) != HAL_OK)
  {
    Error_Handler();
  }
  if (HAL_TIM_PWM_ConfigChannel(&htim1, &sConfigOC, TIM_CHANNEL_2) != HAL_OK)
  {
    Error_Handler();
  }
  if (HAL_TIM_PWM_ConfigChannel(&htim1, &sConfigOC, TIM_CHANNEL_3) != HAL_OK)
  {
    Error_Handler();
  }
  sConfigOC.OCMode = TIM_OCMODE_PWM2;
  sConfigOC.Pulse = (((PWM_PERIOD_CYCLES) / 2) - (HTMIN));
  if (HAL_TIM_PWM_ConfigChannel(&htim1, &sConfigOC, TIM_CHANNEL_4) != HAL_OK)
  {
    Error_Handler();
  }
  sConfigOC.Pulse = (((PWM_PERIOD_CYCLES) / 2) + 1);
  if (HAL_TIM_PWM_ConfigChannel(&htim1, &sConfigOC, TIM_CHANNEL_5) != HAL_OK)
  {
    Error_Handler();
  }
  if (HAL_TIM_PWM_ConfigChannel(&htim1, &sConfigOC, TIM_CHANNEL_6) != HAL_OK)
  {
    Error_Handler();
  }
  sBreakDeadTimeConfig.OffStateRunMode = TIM_OSSR_ENABLE;
  sBreakDeadTimeConfig.OffStateIDLEMode = TIM_OSSI_ENABLE;
  sBreakDeadTimeConfig.LockLevel = TIM_LOCKLEVEL_OFF;
  sBreakDeadTimeConfig.DeadTime = ((DEAD_TIME_COUNTS) / 2);
  sBreakDeadTimeConfig.BreakState = TIM_BREAK_DISABLE;
  sBreakDeadTimeConfig.BreakPolarity = TIM_BREAKPOLARITY_HIGH;
  sBreakDeadTimeConfig.BreakFilter = 0;
  sBreakDeadTimeConfig.BreakAFMode = TIM_BREAK_AFMODE_INPUT;
  sBreakDeadTimeConfig.Break2State = TIM_BREAK2_DISABLE;
  sBreakDeadTimeConfig.Break2Polarity = TIM_BREAK2POLARITY_HIGH;
  sBreakDeadTimeConfig.Break2Filter = 3;
  sBreakDeadTimeConfig.Break2AFMode = TIM_BREAK_AFMODE_INPUT;
  sBreakDeadTimeConfig.AutomaticOutput = TIM_AUTOMATICOUTPUT_DISABLE;
  if (HAL_TIMEx_ConfigBreakDeadTime(&htim1, &sBreakDeadTimeConfig) != HAL_OK)
  {
    Error_Handler();
  }
  HAL_TIM_MspPostInit(&htim1);

}

static void MX_TIM4_Init(void)
{

  TIM_ClockConfigTypeDef sClockSourceConfig = {0};
  TIM_HallSensor_InitTypeDef sConfig = {0};
  TIM_MasterConfigTypeDef sMasterConfig = {0};

  htim4.Instance = TIM4;
  htim4.Init.Prescaler = 0;
  htim4.Init.CounterMode = TIM_COUNTERMODE_UP;
  htim4.Init.Period = M1_HALL_TIM_PERIOD;
  htim4.Init.ClockDivision = TIM_CLOCKDIVISION_DIV1;
  htim4.Init.AutoReloadPreload = TIM_AUTORELOAD_PRELOAD_DISABLE;
  if (HAL_TIM_Base_Init(&htim4) != HAL_OK)
  {
    Error_Handler();
  }
  sClockSourceConfig.ClockSource = TIM_CLOCKSOURCE_INTERNAL;
  if (HAL_TIM_ConfigClockSource(&htim4, &sClockSourceConfig) != HAL_OK)
  {
    Error_Handler();
  }
  sConfig.IC1Polarity = TIM_ICPOLARITY_RISING;
  sConfig.IC1Prescaler = TIM_ICPSC_DIV1;
  sConfig.IC1Filter = M1_HALL_IC_FILTER;
  sConfig.Commutation_Delay = 0;
  if (HAL_TIMEx_HallSensor_Init(&htim4, &sConfig) != HAL_OK)
  {
    Error_Handler();
  }
  sMasterConfig.MasterOutputTrigger = TIM_TRGO_OC2REF;
  sMasterConfig.MasterSlaveMode = TIM_MASTERSLAVEMODE_DISABLE;
  if (HAL_TIMEx_MasterConfigSynchronization(&htim4, &sMasterConfig) != HAL_OK)
  {
    Error_Handler();
  }

}

static void MX_USART2_UART_Init(void)
{

  huart2.Instance = USART2;
  huart2.Init.BaudRate = 115200;
  huart2.Init.WordLength = UART_WORDLENGTH_8B;
  huart2.Init.StopBits = UART_STOPBITS_1;
  huart2.Init.Parity = UART_PARITY_NONE;
  huart2.Init.Mode = UART_MODE_TX_RX;
  huart2.Init.HwFlowCtl = UART_HWCONTROL_NONE;
  huart2.Init.OverSampling = UART_OVERSAMPLING_16;
  huart2.Init.OneBitSampling = UART_ONE_BIT_SAMPLE_DISABLE;
  huart2.Init.ClockPrescaler = UART_PRESCALER_DIV1;
  huart2.AdvancedInit.AdvFeatureInit = UART_ADVFEATURE_NO_INIT;
  if (HAL_UART_Init(&huart2) != HAL_OK)
  {
    Error_Handler();
  }
  if (HAL_UARTEx_SetTxFifoThreshold(&huart2, UART_TXFIFO_THRESHOLD_1_8) != HAL_OK)
  {
    Error_Handler();
  }
  if (HAL_UARTEx_SetRxFifoThreshold(&huart2, UART_RXFIFO_THRESHOLD_1_8) != HAL_OK)
  {
    Error_Handler();
  }
  if (HAL_UARTEx_DisableFifoMode(&huart2) != HAL_OK)
  {
    Error_Handler();
  }

}

static void MX_USART3_UART_Init(void)
{

  huart3.Instance = USART3;
  huart3.Init.BaudRate = 115200;
  huart3.Init.WordLength = UART_WORDLENGTH_8B;
  huart3.Init.StopBits = UART_STOPBITS_1;
  huart3.Init.Parity = UART_PARITY_NONE;
  huart3.Init.Mode = UART_MODE_TX_RX;
  huart3.Init.HwFlowCtl = UART_HWCONTROL_NONE;
  huart3.Init.OverSampling = UART_OVERSAMPLING_16;
  huart3.Init.OneBitSampling = UART_ONE_BIT_SAMPLE_DISABLE;
  huart3.Init.ClockPrescaler = UART_PRESCALER_DIV1;
  huart3.AdvancedInit.AdvFeatureInit = UART_ADVFEATURE_NO_INIT;
  if (HAL_UART_Init(&huart3) != HAL_OK)
  {
    Error_Handler();
  }
  if (HAL_UARTEx_SetTxFifoThreshold(&huart3, UART_TXFIFO_THRESHOLD_1_8) != HAL_OK)
  {
    Error_Handler();
  }
  if (HAL_UARTEx_SetRxFifoThreshold(&huart3, UART_RXFIFO_THRESHOLD_1_8) != HAL_OK)
  {
    Error_Handler();
  }
  if (HAL_UARTEx_DisableFifoMode(&huart3) != HAL_OK)
  {
    Error_Handler();
  }

}

static void MX_DMA_Init(void)
{

  /* DMA controller clock enable */
  __HAL_RCC_DMAMUX1_CLK_ENABLE();
  __HAL_RCC_DMA1_CLK_ENABLE();

}

static void MX_GPIO_Init(void)
{
  GPIO_InitTypeDef GPIO_InitStruct = {0};

  /* GPIO Ports Clock Enable */
  __HAL_RCC_GPIOC_CLK_ENABLE();
  __HAL_RCC_GPIOA_CLK_ENABLE();
  __HAL_RCC_GPIOB_CLK_ENABLE();
  __HAL_RCC_GPIOE_CLK_ENABLE();
  __HAL_RCC_GPIOD_CLK_ENABLE();

  /*Configure GPIO pin Output Level */
  HAL_GPIO_WritePin(GPIOC, LED_B_Pin|LED_R_Pin|LED_G_Pin|DIP0_Pin
                          |DIP1_Pin|DIP2_Pin|DIP3_Pin|ADC_SEL3_Pin
                          |ADC_nEN_Pin, GPIO_PIN_RESET);

  /*Configure GPIO pin Output Level */
  HAL_GPIO_WritePin(GPIOA, TXEN_485_Pin|ADC_SEL0_Pin|ADC_SEL1_Pin|ADC_SEL2_Pin
                          |ADS_CLK_Pin|ADS_PDWN_Pin|ADS_GAIN0_Pin|ADS_GAIN1_Pin, GPIO_PIN_RESET);

  /*Configure GPIO pin Output Level */
  HAL_GPIO_WritePin(GD_WAKE_GPIO_Port, GD_WAKE_Pin, GPIO_PIN_SET);

  /*Configure GPIO pins : LED_B_Pin LED_R_Pin LED_G_Pin DIP0_Pin
                           DIP1_Pin DIP2_Pin DIP3_Pin ADC_SEL3_Pin
                           ADC_nEN_Pin */
  GPIO_InitStruct.Pin = LED_B_Pin|LED_R_Pin|LED_G_Pin|DIP0_Pin
                          |DIP1_Pin|DIP2_Pin|DIP3_Pin|ADC_SEL3_Pin
                          |ADC_nEN_Pin;
  GPIO_InitStruct.Mode = GPIO_MODE_OUTPUT_PP;
  GPIO_InitStruct.Pull = GPIO_NOPULL;
  GPIO_InitStruct.Speed = GPIO_SPEED_FREQ_LOW;
  HAL_GPIO_Init(GPIOC, &GPIO_InitStruct);

  /*Configure GPIO pins : TXEN_485_Pin ADC_SEL0_Pin ADC_SEL1_Pin ADC_SEL2_Pin
                           ADS_CLK_Pin ADS_PDWN_Pin ADS_GAIN0_Pin ADS_GAIN1_Pin */
  GPIO_InitStruct.Pin = TXEN_485_Pin|ADC_SEL0_Pin|ADC_SEL1_Pin|ADC_SEL2_Pin
                          |ADS_CLK_Pin|ADS_PDWN_Pin|ADS_GAIN0_Pin|ADS_GAIN1_Pin;
  GPIO_InitStruct.Mode = GPIO_MODE_OUTPUT_PP;
  GPIO_InitStruct.Pull = GPIO_NOPULL;
  GPIO_InitStruct.Speed = GPIO_SPEED_FREQ_LOW;
  HAL_GPIO_Init(GPIOA, &GPIO_InitStruct);

  /*Configure GPIO pin : HALL_0_Pin */
  GPIO_InitStruct.Pin = HALL_0_Pin;
  GPIO_InitStruct.Mode = GPIO_MODE_INPUT;
  GPIO_InitStruct.Pull = GPIO_NOPULL;
  HAL_GPIO_Init(HALL_0_GPIO_Port, &GPIO_InitStruct);

  /*Configure GPIO pin : GD_WAKE_Pin */
  GPIO_InitStruct.Pin = GD_WAKE_Pin;
  GPIO_InitStruct.Mode = GPIO_MODE_OUTPUT_PP;
  GPIO_InitStruct.Pull = GPIO_NOPULL;
  GPIO_InitStruct.Speed = GPIO_SPEED_FREQ_LOW;
  HAL_GPIO_Init(GD_WAKE_GPIO_Port, &GPIO_InitStruct);

  /*Configure GPIO pins : GD_READY_Pin GD_NFAULT_Pin */
  GPIO_InitStruct.Pin = GD_READY_Pin|GD_NFAULT_Pin;
  GPIO_InitStruct.Mode = GPIO_MODE_INPUT;
  GPIO_InitStruct.Pull = GPIO_PULLUP;
  HAL_GPIO_Init(GPIOE, &GPIO_InitStruct);

  /*Configure GPIO pin : ADS_DOUT_Pin */
  GPIO_InitStruct.Pin = ADS_DOUT_Pin;
  GPIO_InitStruct.Mode = GPIO_MODE_INPUT;
  GPIO_InitStruct.Pull = GPIO_NOPULL;
  HAL_GPIO_Init(ADS_DOUT_GPIO_Port, &GPIO_InitStruct);

  /*Configure GPIO pin : Start_Stop_Pin */
  GPIO_InitStruct.Pin = Start_Stop_Pin;
  GPIO_InitStruct.Mode = GPIO_MODE_IT_RISING;
  GPIO_InitStruct.Pull = GPIO_NOPULL;
  HAL_GPIO_Init(Start_Stop_GPIO_Port, &GPIO_InitStruct);

  /* EXTI interrupt init*/
  HAL_NVIC_SetPriority(EXTI2_IRQn, 3, 0);
  HAL_NVIC_EnableIRQ(EXTI2_IRQn);

}

void Error_Handler(void)
{
  __disable_irq();
  while (1)
  {
  }
}
